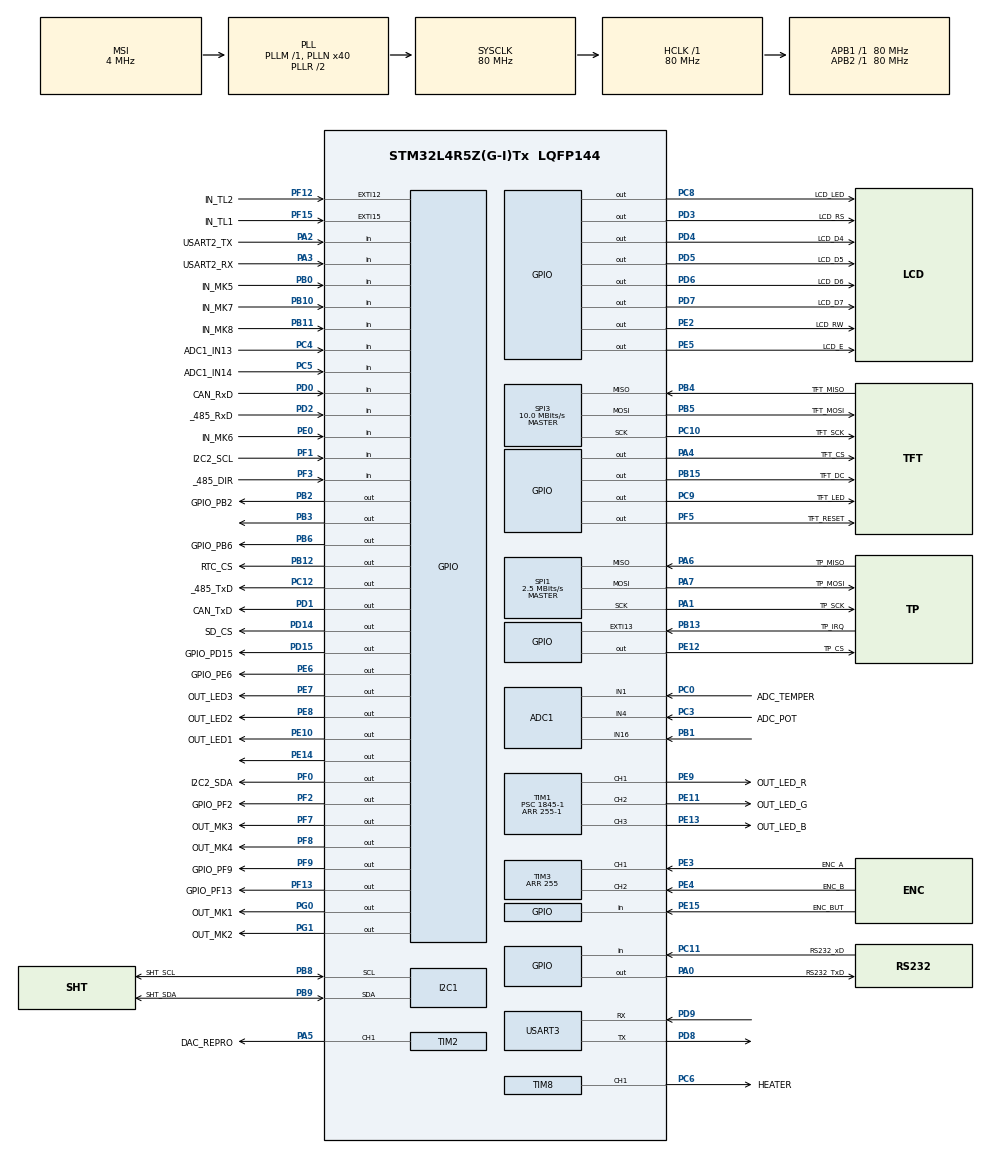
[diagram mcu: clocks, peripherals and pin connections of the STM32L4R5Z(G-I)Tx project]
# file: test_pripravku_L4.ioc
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ADC1.Channel-0\#ChannelRegularConversion=ADC_CHANNEL_4
ADC1.Channel-1\#ChannelRegularConversion=ADC_CHANNEL_1
ADC1.ContinuousConvMode=ENABLE
ADC1.NbrOfConversion=2
ADC1.NbrOfConversionFlag=1
ADC1.OffsetNumber-0\#ChannelRegularConversion=ADC_OFFSET_NONE
ADC1.OffsetNumber-1\#ChannelRegularConversion=ADC_OFFSET_NONE
ADC1.Rank-0\#ChannelRegularConversion=1
ADC1.Rank-1\#ChannelRegularConversion=2
ADC1.SamplingTime-0\#ChannelRegularConversion=ADC_SAMPLETIME_2CYCLES_5
ADC1.SamplingTime-1\#ChannelRegularConversion=ADC_SAMPLETIME_2CYCLES_5
ADC1.master=1
Dma.ADC1.1.Direction=DMA_PERIPH_TO_MEMORY
Dma.ADC1.1.EventEnable=DISABLE
Dma.ADC1.1.Instance=DMA1_Channel2
Dma.ADC1.1.MemDataAlignment=DMA_MDATAALIGN_WORD
Dma.ADC1.1.MemInc=DMA_MINC_ENABLE
Dma.ADC1.1.Mode=DMA_CIRCULAR
Dma.ADC1.1.PeriphDataAlignment=DMA_PDATAALIGN_WORD
Dma.ADC1.1.PeriphInc=DMA_PINC_DISABLE
Dma.ADC1.1.Polarity=HAL_DMAMUX_REQUEST_GEN_RISING
Dma.ADC1.1.Priority=DMA_PRIORITY_LOW
Dma.ADC1.1.RequestNumber=1
Dma.ADC1.1.SignalID=NONE
Dma.ADC1.1.SyncEnable=DISABLE
Dma.ADC1.1.SyncPolarity=HAL_DMAMUX_SYNC_NO_EVENT
Dma.ADC1.1.SyncRequestNumber=1
Dma.ADC1.1.SyncSignalID=NONE
Dma.Request0=SPI3_TX
Dma.Request1=ADC1
Dma.SPI3_TX.0.Direction=DMA_MEMORY_TO_PERIPH
Dma.SPI3_TX.0.EventEnable=DISABLE
Dma.SPI3_TX.0.Instance=DMA1_Channel1
Dma.SPI3_TX.0.MemDataAlignment=DMA_MDATAALIGN_BYTE
Dma.SPI3_TX.0.MemInc=DMA_MINC_ENABLE
Dma.SPI3_TX.0.Mode=DMA_CIRCULAR
Dma.SPI3_TX.0.PeriphDataAlignment=DMA_PDATAALIGN_BYTE
Dma.SPI3_TX.0.PeriphInc=DMA_PINC_DISABLE
Dma.SPI3_TX.0.Polarity=HAL_DMAMUX_REQUEST_GEN_RISING
Dma.SPI3_TX.0.Priority=DMA_PRIORITY_LOW
Dma.SPI3_TX.0.RequestNumber=1
Dma.SPI3_TX.0.SignalID=NONE
Dma.SPI3_TX.0.SyncEnable=DISABLE
Dma.SPI3_TX.0.SyncPolarity=HAL_DMAMUX_SYNC_NO_EVENT
Dma.SPI3_TX.0.SyncRequestNumber=1
Dma.SPI3_TX.0.SyncSignalID=NONE
Mcu.Family=STM32L4
Mcu.Name=STM32L4R5Z(G-I)Tx
Mcu.Package=LQFP144
NVIC.ADC1_IRQn=true\:0\:0\:false\:false\:true\:true\:true
NVIC.DMA1_Channel1_IRQn=true\:0\:0\:false\:false\:true\:false\:true
NVIC.DMA1_Channel2_IRQn=true\:0\:0\:false\:false\:true\:false\:true
NVIC.EXTI15_10_IRQn=true\:1\:0\:true\:false\:true\:true\:true
NVIC.PriorityGroup=NVIC_PRIORITYGROUP_4
NVIC.TIM3_IRQn=true\:0\:0\:false\:false\:true\:true\:true
NVIC.TIM4_IRQn=true\:0\:0\:false\:false\:true\:true\:true
NVIC.TIM5_IRQn=true\:0\:0\:false\:false\:true\:true\:true
NVIC.TIM6_DAC_IRQn=true\:0\:0\:false\:false\:true\:true\:true
PA0.GPIO_Label=RS232_TxD
PA0.Signal=GPIO_Output
PA1.GPIO_Label=TP_SCK
PA1.Mode=Full_Duplex_Master
PA1.Signal=SPI1_SCK
PA2.GPIO_Label=USART2_TX
PA2.Signal=GPIO_Input
PA3.GPIO_Label=USART2_RX
PA3.Signal=GPIO_Input
PA4.GPIO_Label=TFT_CS
PA4.GPIO_Speed=GPIO_SPEED_FREQ_HIGH
PA4.PinState=GPIO_PIN_RESET
PA4.Signal=GPIO_Output
PA5.GPIO_Label=DAC_REPRO
PA5.Signal=S_TIM2_CH1
PA6.GPIO_Label=TP_MISO
PA6.Mode=Full_Duplex_Master
PA6.Signal=SPI1_MISO
PA7.GPIO_Label=TP_MOSI
PA7.Mode=Full_Duplex_Master
PA7.Signal=SPI1_MOSI
PB0.GPIO_Label=IN_MK5
PB0.Signal=GPIO_Input
PB1.Signal=ADCx_IN16
PB10.GPIO_Label=IN_MK7
PB10.Signal=GPIO_Input
PB11.GPIO_Label=IN_MK8
PB11.Signal=GPIO_Input
PB12.GPIO_Label=RTC_CS
PB12.GPIO_Speed=GPIO_SPEED_FREQ_HIGH
PB12.Signal=GPIO_Output
PB13.GPIO_Label=TP_IRQ
PB13.GPIO_ModeDefaultEXTI=GPIO_MODE_IT_RISING_FALLING
PB13.GPIO_PuPd=GPIO_PULLUP
PB13.Signal=GPXTI13
PB15.GPIO_Label=TFT_DC
PB15.GPIO_Speed=GPIO_SPEED_FREQ_HIGH
PB15.Signal=GPIO_Output
PB2.GPIO_Label=GPIO_PB2
PB2.Signal=GPIO_Output
PB3\ (JTDO/TRACESWO).Signal=GPIO_Output
PB4\ (NJTRST).GPIO_Label=TFT_MISO
PB4\ (NJTRST).Mode=Full_Duplex_Master
PB4\ (NJTRST).Signal=SPI3_MISO
PB5.GPIO_Label=TFT_MOSI
PB5.Mode=Full_Duplex_Master
PB5.Signal=SPI3_MOSI
PB6.GPIO_Label=GPIO_PB6
PB6.Signal=GPIO_Output
PB8.GPIO_Label=SHT_SCL
PB8.Mode=I2C
PB8.Signal=I2C1_SCL
PB9.GPIO_Label=SHT_SDA
PB9.Mode=I2C
PB9.Signal=I2C1_SDA
PC0.GPIO_Label=ADC_TEMPER
PC0.Signal=ADCx_IN1
PC10.GPIO_Label=TFT_SCK
PC10.Mode=Full_Duplex_Master
PC10.Signal=SPI3_SCK
PC11.GPIO_Label=RS232_xD
PC11.Signal=GPIO_Input
PC12.GPIO_Label=_485_TxD
PC12.Signal=GPIO_Output
PC3.GPIO_Label=ADC_POT
PC3.Signal=ADCx_IN4
PC4.GPIO_Label=ADC1_IN13
PC4.Signal=GPIO_Input
PC5.GPIO_Label=ADC1_IN14
PC5.Signal=GPIO_Input
PC6.GPIO_Label=HEATER
PC6.Signal=S_TIM8_CH1
PC8.GPIO_Label=LCD_LED
PC8.Signal=GPIO_Output
PC9.GPIO_Label=TFT_LED
PC9.Signal=GPIO_Output
PD0.GPIO_Label=CAN_RxD
PD0.Signal=GPIO_Input
PD1.GPIO_Label=CAN_TxD
PD1.Signal=GPIO_Output
PD14.GPIO_Label=SD_CS
PD14.GPIO_Speed=GPIO_SPEED_FREQ_HIGH
PD14.Signal=GPIO_Output
PD15.GPIO_Label=GPIO_PD15
PD15.Signal=GPIO_Output
PD2.GPIO_Label=_485_RxD
PD2.Signal=GPIO_Input
PD3.GPIO_Label=LCD_RS
PD3.Signal=GPIO_Output
PD4.GPIO_Label=LCD_D4
PD4.Signal=GPIO_Output
PD5.GPIO_Label=LCD_D5
PD5.Signal=GPIO_Output
PD6.GPIO_Label=LCD_D6
PD6.Signal=GPIO_Output
PD7.GPIO_Label=LCD_D7
PD7.Signal=GPIO_Output
PD8.Mode=Asynchronous
PD8.Signal=USART3_TX
PD9.Mode=Asynchronous
PD9.Signal=USART3_RX
PE0.GPIO_Label=IN_MK6
PE0.Signal=GPIO_Input
PE10.GPIO_Label=OUT_LED1
PE10.Signal=GPIO_Output
PE11.GPIO_Label=OUT_LED_G
PE11.Signal=S_TIM1_CH2
PE12.GPIO_Label=TP_CS
PE12.GPIO_Speed=GPIO_SPEED_FREQ_HIGH
PE12.Signal=GPIO_Output
PE13.GPIO_Label=OUT_LED_B
PE13.Signal=S_TIM1_CH3
PE14.Signal=GPIO_Output
PE15.GPIO_Label=ENC_BUT
PE15.Signal=GPIO_Input
PE2.GPIO_Label=LCD_RW
PE2.Signal=GPIO_Output
PE3.GPIO_Label=ENC_A
PE3.Signal=S_TIM3_CH1
PE4.GPIO_Label=ENC_B
PE4.Signal=S_TIM3_CH2
PE5.GPIO_Label=LCD_E
PE5.Signal=GPIO_Output
PE6.GPIO_Label=GPIO_PE6
PE6.Signal=GPIO_Output
PE7.GPIO_Label=OUT_LED3
PE7.Signal=GPIO_Output
PE8.GPIO_Label=OUT_LED2
PE8.Signal=GPIO_Output
PE9.GPIO_Label=OUT_LED_R
PE9.Signal=S_TIM1_CH1
PF0.GPIO_Label=I2C2_SDA
PF0.Signal=GPIO_Output
PF1.GPIO_Label=I2C2_SCL
PF1.Signal=GPIO_Input
PF12.GPIO_Label=IN_TL2
PF12.Signal=GPXTI12
PF13.GPIO_Label=GPIO_PF13
PF13.Signal=GPIO_Output
PF15.GPIO_Label=IN_TL1
PF15.Signal=GPXTI15
PF2.GPIO_Label=GPIO_PF2
PF2.Signal=GPIO_Output
PF3.GPIO_Label=_485_DIR
PF3.Signal=GPIO_Input
PF5.GPIO_Label=TFT_RESET
PF5.GPIO_Speed=GPIO_SPEED_FREQ_HIGH
PF5.Signal=GPIO_Output
PF7.GPIO_Label=OUT_MK3
PF7.GPIO_ModeDefaultOutputPP=GPIO_MODE_OUTPUT_OD
PF7.Signal=GPIO_Output
PF8.GPIO_Label=OUT_MK4
PF8.GPIO_ModeDefaultOutputPP=GPIO_MODE_OUTPUT_OD
PF8.Signal=GPIO_Output
PF9.GPIO_Label=GPIO_PF9
PF9.Signal=GPIO_Output
PG0.GPIO_Label=OUT_MK1
PG0.GPIO_ModeDefaultOutputPP=GPIO_MODE_OUTPUT_OD
PG0.Signal=GPIO_Output
PG1.GPIO_Label=OUT_MK2
PG1.GPIO_ModeDefaultOutputPP=GPIO_MODE_OUTPUT_OD
PG1.Signal=GPIO_Output
PH0-OSC_IN\ (PH0).Mode=HSE-External-Oscillator
PH0-OSC_IN\ (PH0).Signal=RCC_OSC_IN
PH1-OSC_OUT\ (PH1).Mode=HSE-External-Oscillator
PH1-OSC_OUT\ (PH1).Signal=RCC_OSC_OUT
ProjectManager.HeapSize=0x200
ProjectManager.StackSize=0x400
ProjectManager.TargetToolchain=STM32CubeIDE
RCC.48MHZClocksFreq_Value=24000000
RCC.ADCFreq_Value=32000000
RCC.AHBFreq_Value=80000000
RCC.APB1Freq_Value=80000000
RCC.APB1TimFreq_Value=80000000
RCC.APB2Freq_Value=80000000
RCC.APB2TimFreq_Value=80000000
RCC.CortexFreq_Value=80000000
RCC.HCLKFreq_Value=80000000
RCC.HSE_VALUE=8000000
RCC.HSI48_VALUE=48000000
RCC.HSI_VALUE=16000000
RCC.LSE_VALUE=32768
RCC.MSI_VALUE=4000000
RCC.PLLMUL=RCC_PLL_MUL9
RCC.PLLN=40
RCC.PLLSAI1N=16
RCC.PRESCALERUSB=RCC_USBCLKSOURCE_PLL_DIV1_5
RCC.SYSCLKFreq_VALUE=80000000
RCC.SYSCLKSource=RCC_SYSCLKSOURCE_PLLCLK
RCC.SYSCLKSourceVirtual=RCC_SYSCLKSOURCE_PLLCLK
RCC.USBFreq_Value=32000000
RCC.VCOOutputFreq_Value=160000000
SH.ADCx_IN1.0=ADC1_IN1,IN1-Single-Ended
SH.ADCx_IN16.0=ADC1_IN16,IN16-Single-Ended
SH.ADCx_IN4.0=ADC1_IN4,IN4-Single-Ended
SH.S_TIM1_CH1.0=TIM1_CH1,PWM Generation1 CH1
SH.S_TIM1_CH2.0=TIM1_CH2,PWM Generation2 CH2
SH.S_TIM1_CH3.0=TIM1_CH3,PWM Generation3 CH3
SH.S_TIM2_CH1.0=TIM2_CH1,PWM Generation1 CH1
SH.S_TIM3_CH1.0=TIM3_CH1,Encoder_Interface
SH.S_TIM3_CH2.0=TIM3_CH2,Encoder_Interface
SH.S_TIM8_CH1.0=TIM8_CH1,PWM Generation1 CH1
SPI1.BaudRatePrescaler=SPI_BAUDRATEPRESCALER_32
SPI1.CalculateBaudRate=2.5 MBits/s
SPI1.DataSize=SPI_DATASIZE_8BIT
SPI1.Direction=SPI_DIRECTION_2LINES
SPI1.Mode=SPI_MODE_MASTER
SPI1.VirtualType=VM_MASTER
SPI3.BaudRatePrescaler=SPI_BAUDRATEPRESCALER_8
SPI3.CalculateBaudRate=10.0 MBits/s
SPI3.DataSize=SPI_DATASIZE_8BIT
SPI3.Direction=SPI_DIRECTION_2LINES
SPI3.Mode=SPI_MODE_MASTER
SPI3.VirtualType=VM_MASTER
TIM1.Channel-PWM\ Generation1\ CH1=TIM_CHANNEL_1
TIM1.Channel-PWM\ Generation2\ CH2=TIM_CHANNEL_2
TIM1.Channel-PWM\ Generation3\ CH3=TIM_CHANNEL_3
TIM1.Period=255-1
TIM1.Prescaler=1845-1
TIM2.Channel-PWM\ Generation1\ CH1=TIM_CHANNEL_1
TIM2.Period=250-1
TIM2.Prescaler=1280-1
TIM2.TIM_MasterOutputTrigger=TIM_TRGO_UPDATE
TIM3.Period=255
TIM3.TIM_MasterOutputTrigger=TIM_TRGO_RESET
TIM4.Period=500-1
TIM4.Prescaler=8000-1
TIM5.Period=500-1
TIM5.Prescaler=8000-1
TIM6.Period=5000-1
TIM6.Prescaler=8000-1
TIM8.Channel-PWM\ Generation1\ CH1=TIM_CHANNEL_1
TIM8.Period=250-1
TIM8.Prescaler=1280-1
TIM8.TIM_MasterOutputTrigger=TIM_TRGO_UPDATE
TIM8.TIM_MasterOutputTrigger2=TIM_TRGO2_UPDATE
USART3.VirtualMode-Asynchronous=VM_ASYNC
VP_RNG_VS_RNG.Mode=RNG_Activate
VP_TIM1_VS_ClockSourceINT.Mode=Internal
VP_TIM2_VS_ClockSourceINT.Mode=Internal
VP_TIM4_VS_ClockSourceINT.Mode=Internal
VP_TIM5_VS_ClockSourceINT.Mode=Internal
VP_TIM6_VS_ClockSourceINT.Mode=Enable_Timer
VP_TIM8_VS_ClockSourceINT.Mode=Internal
board=NUCLEO-L4R5ZI

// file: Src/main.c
/* USER CODE BEGIN Header */
/**
  ******************************************************************************
  *
  * Author: Pavel Vaner
  *
  ******************************************************************************
  */
/* USER CODE END Header */

#include <my_lib_gui.h>
#include <my_lib_ILI9341.h>
#include <my_lib_keypad4x4.h>
#include <my_lib_LCD16x2.h>
#include <my_lib_MCP795.h>
#include <my_lib_STH20.h>
#include <my_lib_XPT2046.h>
#include "main.h"

/* USER CODE BEGIN Includes */
#include "L4_main_header.h"
#include "stm32l4xx_hal.h"
#include <stdbool.h>
#include "math.h"
/* USER CODE END Includes */

/* USER CODE BEGIN PD */
#define PI 3.1415926
/* USER CODE END PD */

ADC_HandleTypeDef hadc1;
DMA_HandleTypeDef hdma_adc1;

I2C_HandleTypeDef hi2c1;

RNG_HandleTypeDef hrng;

SPI_HandleTypeDef hspi1;
SPI_HandleTypeDef hspi3;
DMA_HandleTypeDef hdma_spi3_tx;

TIM_HandleTypeDef htim1;
TIM_HandleTypeDef htim2;
TIM_HandleTypeDef htim3;
TIM_HandleTypeDef htim4;
TIM_HandleTypeDef htim5;
TIM_HandleTypeDef htim6;
TIM_HandleTypeDef htim8;

UART_HandleTypeDef huart3;

/* USER CODE BEGIN PV */
extern uint16_t TFT9341_WIDTH;
extern uint16_t TFT9341_HEIGHT;
uint8_t dma_spi_fl=0;
uint32_t dma_spi_cnt=1;
uint8_t TFTstav=0;
char str[16];
char str2[16];
char strENC[16];
bool mySwitches[16];
uint8_t RGBcounter;
uint32_t ADCvalues[2];
uint8_t semafor=0;
bool IRQ_flag=false;
Keypad_WiresTypeDef myKeypadStruct;
char strPOT [16];
uint32_t POTvalue=0;
/* USER CODE END PV */

void SystemClock_Config(void);
static void MX_GPIO_Init(void);
static void MX_DMA_Init(void);
static void MX_SPI1_Init(void);
static void MX_SPI3_Init(void);
static void MX_TIM3_Init(void);
static void MX_ADC1_Init(void);
static void MX_USART3_UART_Init(void);
static void MX_I2C1_Init(void);
static void MX_RNG_Init(void);
static void MX_TIM1_Init(void);
static void MX_TIM2_Init(void);
static void MX_TIM8_Init(void);
static void MX_TIM4_Init(void);
static void MX_TIM5_Init(void);
static void MX_TIM6_Init(void);

/* USER CODE BEGIN 0 */
//metoda pro nastaveni RGB ledky
void set_rgb (uint8_t red, uint8_t green, uint8_t blue) //0 je nejvetsi intenzita
{
	htim1.Instance->CCR1 = green;
	htim1.Instance->CCR2 = red;
	htim1.Instance->CCR3 = blue;
}
//metoda volana pri zmene stavu menu
void StavSwitch(void)
{
	  LCD1602_clear();
	  HAL_TIM_PWM_Stop(&htim1, TIM_CHANNEL_1);
	  HAL_TIM_PWM_Stop(&htim1, TIM_CHANNEL_2);
	  HAL_TIM_PWM_Stop(&htim1, TIM_CHANNEL_3);
	  HAL_TIM_Encoder_Stop_IT(&htim3, TIM_CHANNEL_1);
	  HAL_TIM_PWM_Stop(&htim8, TIM_CHANNEL_1);
	  HAL_TIM_PWM_Stop(&htim2, TIM_CHANNEL_1);
	  HAL_TIM_Base_Stop_IT(&htim4);
	  HAL_TIM_Base_Stop_IT(&htim5);
	  HAL_TIM_Base_Stop_IT(&htim6);
	  HAL_GPIO_WritePin(OUT_LED2_GPIO_Port, OUT_LED2_Pin, RESET);
	  HAL_GPIO_WritePin(OUT_LED1_GPIO_Port, OUT_LED1_Pin, RESET);
	  HAL_GPIO_WritePin(OUT_LED3_GPIO_Port, OUT_LED3_Pin, RESET);
}
/* USER CODE END 0 */

int main(void)
{

  /* MCU Configuration--------------------------------------------------------*/

  /* Reset of all peripherals, Initializes the Flash interface and the Systick. */
  HAL_Init();

  /* Configure the system clock */
  SystemClock_Config();

  /* Initialize all configured peripherals */
  MX_GPIO_Init();
  MX_DMA_Init();
  MX_SPI1_Init();
  MX_SPI3_Init();
  MX_TIM3_Init();
  MX_ADC1_Init();
  MX_USART3_UART_Init();
  MX_I2C1_Init();
  MX_RNG_Init();
  MX_TIM1_Init();
  MX_TIM2_Init();
  MX_TIM8_Init();
  MX_TIM4_Init();
  MX_TIM5_Init();
  MX_TIM6_Init();
  /* USER CODE BEGIN 2 */

  //nastaveni promenne myKeypadStruct pro klavesnici 4x4
  myKeypadStruct.OUT0_Port = OUT_MK1_GPIO_Port;
  myKeypadStruct.OUT1_Port = OUT_MK2_GPIO_Port;
  myKeypadStruct.OUT2_Port = OUT_MK3_GPIO_Port;
  myKeypadStruct.OUT3_Port = OUT_MK4_GPIO_Port;
  myKeypadStruct.OUT0pin=OUT_MK1_Pin;
  myKeypadStruct.OUT1pin=OUT_MK2_Pin;
  myKeypadStruct.OUT2pin=OUT_MK3_Pin;
  myKeypadStruct.OUT3pin=OUT_MK4_Pin;
  myKeypadStruct.IN0_Port = IN_MK5_GPIO_Port;
  myKeypadStruct.IN1_Port = IN_MK6_GPIO_Port;
  myKeypadStruct.IN2_Port = IN_MK7_GPIO_Port;
  myKeypadStruct.IN3_Port = IN_MK8_GPIO_Port;
  myKeypadStruct.IN0pin=IN_MK5_Pin;
  myKeypadStruct.IN1pin=IN_MK6_Pin;
  myKeypadStruct.IN2pin=IN_MK7_Pin;
  myKeypadStruct.IN3pin=IN_MK8_Pin;
  //inicializace vsech periferií
  Keypad4x4_Init(&myKeypadStruct);//klavesnice 4x4
  HAL_GPIO_WritePin(LCD_RW_GPIO_Port, LCD_RW_Pin, RESET);
  LCD1602_Begin4BIT(LCD_RS_GPIO_Port,LCD_RS_Pin,LCD_E_GPIO_Port,LCD_E_Pin,LCD_D4_GPIO_Port,LCD_D4_Pin,LCD_D5_Pin,LCD_D6_Pin,LCD_D7_Pin); //LCD dvouradkovy displej
  LCD1602_noCursor();
  LCD1602_noBlink();
  SHT20_Init(&hi2c1);//SHT20 environmentalni cidlo
  TFT9341_Init(TFT_CS_GPIO_Port, TFT_CS_Pin, TFT_DC_GPIO_Port, TFT_DC_Pin, TFT_RESET_GPIO_Port, TFT_RESET_Pin); //TFT displej
  TFT9341_SetRotation(4);
  GUI_page_main();
  XPT2046_Init(&hspi1, TP_CS_GPIO_Port, TP_CS_Pin, TP_IRQ_GPIO_Port, TP_IRQ_Pin); //touch screen
  /* USER CODE END 2 */

  /* Infinite loop */
  /* USER CODE BEGIN WHILE */
  while (1)
  {
	  //pokud bylo vyvoláno přerušení dotykem obrazovky
	  if(IRQ_flag==true)
	  {
		  StavSwitch();
		  IRQ_flag=false;
	  }
	  switch(TFTstav)
	  {
	  	  	case 1://malovani
	  	  		break;
			case 2: //encoder zmena rgb plus hodnota na displej a potak na displej
				HAL_TIM_PWM_Start (&htim1, TIM_CHANNEL_1);
				HAL_TIM_PWM_Start (&htim1, TIM_CHANNEL_2);
				HAL_TIM_PWM_Start (&htim1, TIM_CHANNEL_3);
				HAL_TIM_Encoder_Start_IT(&htim3, TIM_CHANNEL_1);
				RGBcounter=TIM3->CNT;
				LCD1602_1stLine();
				sprintf(strENC,"Encoder:%3d",RGBcounter);
				LCD1602_print(strENC);
				RGBcounter=RGBcounter%6;
				switch(RGBcounter)
				{
						case 0: //red
							set_rgb (0,255,255);
							break;
						case 1: //green
							set_rgb (255,0,255);
							break;
						case 2: //blue
							set_rgb (255,255,0);
							break;
						case 3: //yellow
							set_rgb (0,0,255);
							break;
						case 4: //Cyan
							set_rgb (255,0,0);
							break;
						case 5: //Magenta
							set_rgb (0,255,0);
							break;
				  }
				  HAL_ADC_Start(&hadc1);
			      HAL_ADC_PollForConversion(&hadc1,100);
			      POTvalue = ceil(((float)HAL_ADC_GetValue(&hadc1))/40.3);
			      HAL_ADC_Stop (&hadc1);
			      LCD1602_2ndLine();
			      sprintf(strPOT,"Potak:%3d", POTvalue);
			      LCD1602_print(strPOT);

				break;
			case 3: //teplota a vlhkost
				SHT20_GetValue();
				LCD1602_1stLine();
				sprintf(str,"Teplota:%.*f",2,sht20_info.tempreture);
				LCD1602_print(str);
				LCD1602_2ndLine();
				sprintf(str2,"Vlhkost:%.*f",2, sht20_info.humidity);
				LCD1602_print(str2);
				HAL_Delay(1000);
				break;
			case 4://klavesnice
				LCD1602_1stLine();
				LCD1602_print("Stisknuto:");
				Keypad4x4_ReadKeypad(mySwitches);
				LCD1602_2ndLine();
				uint8_t strIndex=0;
				char data_keys[16];
				for(uint8_t j=0;j<16;j++)
				{
					data_keys[j]=' ';
				}
				uint8_t k=0;
				for(uint8_t i=0;i<16;i++)
				{
					if(!mySwitches[i])
					{
						data_keys[k]=Keypad4x4_GetChar(i);
						k++;
					}
				}
				LCD1602_print(data_keys);
				break;
			case 5://NTC/heater
				HAL_TIM_PWM_Start(&htim8, TIM_CHANNEL_1);   //heater
				HAL_ADC_Start_DMA(&hadc1, ADCvalues, 2);
				LCD1602_1stLine();
				POTvalue=ceil(((float)ADCvalues[0])/40.3);
				sprintf(str,"HEATER:%3d",POTvalue);
				LCD1602_print(str);
				LCD1602_2ndLine();
				sprintf(str2,"NTC:%3d", ADCvalues[1]);
				LCD1602_print(str2);
				HAL_ADC_Stop_DMA(&hadc1);
				htim8.Instance->CCR1=POTvalue;
				break;
			case 6://reproduktor
				HAL_TIM_PWM_Start(&htim2, TIM_CHANNEL_1);   //reproduktor
				HAL_ADC_Start_DMA(&hadc1, ADCvalues, 2);
				LCD1602_1stLine();
				POTvalue=ceil(((float)ADCvalues[0])/40.3);
				sprintf(str,"REPRO:%3d",POTvalue);
				LCD1602_print(str);
				HAL_ADC_Stop_DMA(&hadc1);
				htim2.Instance->CCR1=POTvalue;
				break;
			case 7://semafor
				HAL_TIM_PWM_Start (&htim1, TIM_CHANNEL_1);
				HAL_TIM_PWM_Start (&htim1, TIM_CHANNEL_2);
				HAL_TIM_PWM_Start (&htim1, TIM_CHANNEL_3);
				HAL_TIM_Base_Start_IT(&htim6);
				break;
			case 8://tlacitka
					// osetrani tlacitka metodou polling reaguje na sestupnou hranu
				  if(HAL_GPIO_ReadPin(ENC_BUT_GPIO_Port, ENC_BUT_Pin)==RESET)
				  {
					  while(HAL_GPIO_ReadPin(ENC_BUT_GPIO_Port, ENC_BUT_Pin)!=SET)
					  {
						  HAL_Delay(30);
					  }
					  HAL_GPIO_TogglePin(OUT_LED1_GPIO_Port, OUT_LED1_Pin);
				  }
				  HAL_Delay(10);
				break;
	  }
    /* USER CODE END WHILE */

  }
}

void SystemClock_Config(void)
{
  RCC_OscInitTypeDef RCC_OscInitStruct = {0};
  RCC_ClkInitTypeDef RCC_ClkInitStruct = {0};
  RCC_PeriphCLKInitTypeDef PeriphClkInit = {0};

  /** Configure the main internal regulator output voltage
  */
  if (HAL_PWREx_ControlVoltageScaling(PWR_REGULATOR_VOLTAGE_SCALE1) != HAL_OK)
  {
    Error_Handler();
  }
  /** Initializes the CPU, AHB and APB busses clocks
  */
  RCC_OscInitStruct.OscillatorType = RCC_OSCILLATORTYPE_MSI;
  RCC_OscInitStruct.MSIState = RCC_MSI_ON;
  RCC_OscInitStruct.MSICalibrationValue = 0;
  RCC_OscInitStruct.MSIClockRange = RCC_MSIRANGE_6;
  RCC_OscInitStruct.PLL.PLLState = RCC_PLL_ON;
  RCC_OscInitStruct.PLL.PLLSource = RCC_PLLSOURCE_MSI;
  RCC_OscInitStruct.PLL.PLLM = 1;
  RCC_OscInitStruct.PLL.PLLN = 40;
  RCC_OscInitStruct.PLL.PLLP = RCC_PLLP_DIV2;
  RCC_OscInitStruct.PLL.PLLQ = RCC_PLLQ_DIV2;
  RCC_OscInitStruct.PLL.PLLR = RCC_PLLR_DIV2;
  if (HAL_RCC_OscConfig(&RCC_OscInitStruct) != HAL_OK)
  {
    Error_Handler();
  }
  /** Initializes the CPU, AHB and APB busses clocks
  */
  RCC_ClkInitStruct.ClockType = RCC_CLOCKTYPE_HCLK|RCC_CLOCKTYPE_SYSCLK
                              |RCC_CLOCKTYPE_PCLK1|RCC_CLOCKTYPE_PCLK2;
  RCC_ClkInitStruct.SYSCLKSource = RCC_SYSCLKSOURCE_PLLCLK;
  RCC_ClkInitStruct.AHBCLKDivider = RCC_SYSCLK_DIV1;
  RCC_ClkInitStruct.APB1CLKDivider = RCC_HCLK_DIV1;
  RCC_ClkInitStruct.APB2CLKDivider = RCC_HCLK_DIV1;

  if (HAL_RCC_ClockConfig(&RCC_ClkInitStruct, FLASH_LATENCY_3) != HAL_OK)
  {
    Error_Handler();
  }
  PeriphClkInit.PeriphClockSelection = RCC_PERIPHCLK_USART3|RCC_PERIPHCLK_I2C1
                              |RCC_PERIPHCLK_RNG|RCC_PERIPHCLK_ADC;
  PeriphClkInit.Usart3ClockSelection = RCC_USART3CLKSOURCE_PCLK1;
  PeriphClkInit.I2c1ClockSelection = RCC_I2C1CLKSOURCE_PCLK1;
  PeriphClkInit.AdcClockSelection = RCC_ADCCLKSOURCE_PLLSAI1;
  PeriphClkInit.RngClockSelection = RCC_RNGCLKSOURCE_PLLSAI1;
  PeriphClkInit.PLLSAI1.PLLSAI1Source = RCC_PLLSOURCE_MSI;
  PeriphClkInit.PLLSAI1.PLLSAI1M = 1;
  PeriphClkInit.PLLSAI1.PLLSAI1N = 16;
  PeriphClkInit.PLLSAI1.PLLSAI1P = RCC_PLLP_DIV2;
  PeriphClkInit.PLLSAI1.PLLSAI1Q = RCC_PLLQ_DIV2;
  PeriphClkInit.PLLSAI1.PLLSAI1R = RCC_PLLR_DIV2;
  PeriphClkInit.PLLSAI1.PLLSAI1ClockOut = RCC_PLLSAI1_48M2CLK|RCC_PLLSAI1_ADC1CLK;
  if (HAL_RCCEx_PeriphCLKConfig(&PeriphClkInit) != HAL_OK)
  {
    Error_Handler();
  }
}

static void MX_ADC1_Init(void)
{

  ADC_ChannelConfTypeDef sConfig = {0};

  /** Common config
  */
  hadc1.Instance = ADC1;
  hadc1.Init.ClockPrescaler = ADC_CLOCK_ASYNC_DIV1;
  hadc1.Init.Resolution = ADC_RESOLUTION_12B;
  hadc1.Init.DataAlign = ADC_DATAALIGN_RIGHT;
  hadc1.Init.ScanConvMode = ADC_SCAN_ENABLE;
  hadc1.Init.EOCSelection = ADC_EOC_SINGLE_CONV;
  hadc1.Init.LowPowerAutoWait = DISABLE;
  hadc1.Init.ContinuousConvMode = ENABLE;
  hadc1.Init.NbrOfConversion = 2;
  hadc1.Init.DiscontinuousConvMode = DISABLE;
  hadc1.Init.NbrOfDiscConversion = 1;
  hadc1.Init.ExternalTrigConv = ADC_SOFTWARE_START;
  hadc1.Init.ExternalTrigConvEdge = ADC_EXTERNALTRIGCONVEDGE_NONE;
  hadc1.Init.DMAContinuousRequests = DISABLE;
  hadc1.Init.Overrun = ADC_OVR_DATA_PRESERVED;
  hadc1.Init.OversamplingMode = DISABLE;
  if (HAL_ADC_Init(&hadc1) != HAL_OK)
  {
    Error_Handler();
  }
  /** Configure Regular Channel
  */
  sConfig.Channel = ADC_CHANNEL_4;
  sConfig.Rank = ADC_REGULAR_RANK_1;
  sConfig.SamplingTime = ADC_SAMPLETIME_2CYCLES_5;
  sConfig.SingleDiff = ADC_SINGLE_ENDED;
  sConfig.OffsetNumber = ADC_OFFSET_NONE;
  sConfig.Offset = 0;
  if (HAL_ADC_ConfigChannel(&hadc1, &sConfig) != HAL_OK)
  {
    Error_Handler();
  }
  /** Configure Regular Channel
  */
  sConfig.Channel = ADC_CHANNEL_1;
  sConfig.Rank = ADC_REGULAR_RANK_2;
  if (HAL_ADC_ConfigChannel(&hadc1, &sConfig) != HAL_OK)
  {
    Error_Handler();
  }

}

static void MX_I2C1_Init(void)
{

  hi2c1.Instance = I2C1;
  hi2c1.Init.Timing = 0x10909CEC;
  hi2c1.Init.OwnAddress1 = 0;
  hi2c1.Init.AddressingMode = I2C_ADDRESSINGMODE_7BIT;
  hi2c1.Init.DualAddressMode = I2C_DUALADDRESS_DISABLE;
  hi2c1.Init.OwnAddress2 = 0;
  hi2c1.Init.OwnAddress2Masks = I2C_OA2_NOMASK;
  hi2c1.Init.GeneralCallMode = I2C_GENERALCALL_DISABLE;
  hi2c1.Init.NoStretchMode = I2C_NOSTRETCH_DISABLE;
  if (HAL_I2C_Init(&hi2c1) != HAL_OK)
  {
    Error_Handler();
  }
  /** Configure Analogue filter
  */
  if (HAL_I2CEx_ConfigAnalogFilter(&hi2c1, I2C_ANALOGFILTER_ENABLE) != HAL_OK)
  {
    Error_Handler();
  }
  /** Configure Digital filter
  */
  if (HAL_I2CEx_ConfigDigitalFilter(&hi2c1, 0) != HAL_OK)
  {
    Error_Handler();
  }

}

static void MX_RNG_Init(void)
{

  hrng.Instance = RNG;
  hrng.Init.ClockErrorDetection = RNG_CED_ENABLE;
  if (HAL_RNG_Init(&hrng) != HAL_OK)
  {
    Error_Handler();
  }

}

static void MX_SPI1_Init(void)
{

  /* SPI1 parameter configuration*/
  hspi1.Instance = SPI1;
  hspi1.Init.Mode = SPI_MODE_MASTER;
  hspi1.Init.Direction = SPI_DIRECTION_2LINES;
  hspi1.Init.DataSize = SPI_DATASIZE_8BIT;
  hspi1.Init.CLKPolarity = SPI_POLARITY_LOW;
  hspi1.Init.CLKPhase = SPI_PHASE_1EDGE;
  hspi1.Init.NSS = SPI_NSS_SOFT;
  hspi1.Init.BaudRatePrescaler = SPI_BAUDRATEPRESCALER_32;
  hspi1.Init.FirstBit = SPI_FIRSTBIT_MSB;
  hspi1.Init.TIMode = SPI_TIMODE_DISABLE;
  hspi1.Init.CRCCalculation = SPI_CRCCALCULATION_DISABLE;
  hspi1.Init.CRCPolynomial = 7;
  hspi1.Init.CRCLength = SPI_CRC_LENGTH_DATASIZE;
  hspi1.Init.NSSPMode = SPI_NSS_PULSE_ENABLE;
  if (HAL_SPI_Init(&hspi1) != HAL_OK)
  {
    Error_Handler();
  }

}

static void MX_SPI3_Init(void)
{

  /* SPI3 parameter configuration*/
  hspi3.Instance = SPI3;
  hspi3.Init.Mode = SPI_MODE_MASTER;
  hspi3.Init.Direction = SPI_DIRECTION_2LINES;
  hspi3.Init.DataSize = SPI_DATASIZE_8BIT;
  hspi3.Init.CLKPolarity = SPI_POLARITY_LOW;
  hspi3.Init.CLKPhase = SPI_PHASE_1EDGE;
  hspi3.Init.NSS = SPI_NSS_SOFT;
  hspi3.Init.BaudRatePrescaler = SPI_BAUDRATEPRESCALER_8;
  hspi3.Init.FirstBit = SPI_FIRSTBIT_MSB;
  hspi3.Init.TIMode = SPI_TIMODE_DISABLE;
  hspi3.Init.CRCCalculation = SPI_CRCCALCULATION_DISABLE;
  hspi3.Init.CRCPolynomial = 7;
  hspi3.Init.CRCLength = SPI_CRC_LENGTH_DATASIZE;
  hspi3.Init.NSSPMode = SPI_NSS_PULSE_ENABLE;
  if (HAL_SPI_Init(&hspi3) != HAL_OK)
  {
    Error_Handler();
  }

}

static void MX_TIM1_Init(void)
{

  TIM_ClockConfigTypeDef sClockSourceConfig = {0};
  TIM_MasterConfigTypeDef sMasterConfig = {0};
  TIM_OC_InitTypeDef sConfigOC = {0};
  TIM_BreakDeadTimeConfigTypeDef sBreakDeadTimeConfig = {0};

  htim1.Instance = TIM1;
  htim1.Init.Prescaler = 1845-1;
  htim1.Init.CounterMode = TIM_COUNTERMODE_UP;
  htim1.Init.Period = 255-1;
  htim1.Init.ClockDivision = TIM_CLOCKDIVISION_DIV1;
  htim1.Init.RepetitionCounter = 0;
  htim1.Init.AutoReloadPreload = TIM_AUTORELOAD_PRELOAD_DISABLE;
  if (HAL_TIM_Base_Init(&htim1) != HAL_OK)
  {
    Error_Handler();
  }
  sClockSourceConfig.ClockSource = TIM_CLOCKSOURCE_INTERNAL;
  if (HAL_TIM_ConfigClockSource(&htim1, &sClockSourceConfig) != HAL_OK)
  {
    Error_Handler();
  }
  if (HAL_TIM_PWM_Init(&htim1) != HAL_OK)
  {
    Error_Handler();
  }
  sMasterConfig.MasterOutputTrigger = TIM_TRGO_RESET;
  sMasterConfig.MasterOutputTrigger2 = TIM_TRGO2_RESET;
  sMasterConfig.MasterSlaveMode = TIM_MASTERSLAVEMODE_DISABLE;
  if (HAL_TIMEx_MasterConfigSynchronization(&htim1, &sMasterConfig) != HAL_OK)
  {
    Error_Handler();
  }
  sConfigOC.OCMode = TIM_OCMODE_PWM1;
  sConfigOC.Pulse = 0;
  sConfigOC.OCPolarity = TIM_OCPOLARITY_HIGH;
  sConfigOC.OCNPolarity = TIM_OCNPOLARITY_HIGH;
  sConfigOC.OCFastMode = TIM_OCFAST_DISABLE;
  sConfigOC.OCIdleState = TIM_OCIDLESTATE_RESET;
  sConfigOC.OCNIdleState = TIM_OCNIDLESTATE_RESET;
  if (HAL_TIM_PWM_ConfigChannel(&htim1, &sConfigOC, TIM_CHANNEL_1) != HAL_OK)
  {
    Error_Handler();
  }
  if (HAL_TIM_PWM_ConfigChannel(&htim1, &sConfigOC, TIM_CHANNEL_2) != HAL_OK)
  {
    Error_Handler();
  }
  if (HAL_TIM_PWM_ConfigChannel(&htim1, &sConfigOC, TIM_CHANNEL_3) != HAL_OK)
  {
    Error_Handler();
  }
  sBreakDeadTimeConfig.OffStateRunMode = TIM_OSSR_DISABLE;
  sBreakDeadTimeConfig.OffStateIDLEMode = TIM_OSSI_DISABLE;
  sBreakDeadTimeConfig.LockLevel = TIM_LOCKLEVEL_OFF;
  sBreakDeadTimeConfig.DeadTime = 0;
  sBreakDeadTimeConfig.BreakState = TIM_BREAK_DISABLE;
  sBreakDeadTimeConfig.BreakPolarity = TIM_BREAKPOLARITY_HIGH;
  sBreakDeadTimeConfig.BreakFilter = 0;
  sBreakDeadTimeConfig.Break2State = TIM_BREAK2_DISABLE;
  sBreakDeadTimeConfig.Break2Polarity = TIM_BREAK2POLARITY_HIGH;
  sBreakDeadTimeConfig.Break2Filter = 0;
  sBreakDeadTimeConfig.AutomaticOutput = TIM_AUTOMATICOUTPUT_DISABLE;
  if (HAL_TIMEx_ConfigBreakDeadTime(&htim1, &sBreakDeadTimeConfig) != HAL_OK)
  {
    Error_Handler();
  }
  HAL_TIM_MspPostInit(&htim1);

}

static void MX_TIM2_Init(void)
{

  TIM_ClockConfigTypeDef sClockSourceConfig = {0};
  TIM_MasterConfigTypeDef sMasterConfig = {0};
  TIM_OC_InitTypeDef sConfigOC = {0};

  htim2.Instance = TIM2;
  htim2.Init.Prescaler = 1280-1;
  htim2.Init.CounterMode = TIM_COUNTERMODE_UP;
  htim2.Init.Period = 250-1;
  htim2.Init.ClockDivision = TIM_CLOCKDIVISION_DIV1;
  htim2.Init.AutoReloadPreload = TIM_AUTORELOAD_PRELOAD_DISABLE;
  if (HAL_TIM_Base_Init(&htim2) != HAL_OK)
  {
    Error_Handler();
  }
  sClockSourceConfig.ClockSource = TIM_CLOCKSOURCE_INTERNAL;
  if (HAL_TIM_ConfigClockSource(&htim2, &sClockSourceConfig) != HAL_OK)
  {
    Error_Handler();
  }
  if (HAL_TIM_PWM_Init(&htim2) != HAL_OK)
  {
    Error_Handler();
  }
  sMasterConfig.MasterOutputTrigger = TIM_TRGO_UPDATE;
  sMasterConfig.MasterSlaveMode = TIM_MASTERSLAVEMODE_DISABLE;
  if (HAL_TIMEx_MasterConfigSynchronization(&htim2, &sMasterConfig) != HAL_OK)
  {
    Error_Handler();
  }
  sConfigOC.OCMode = TIM_OCMODE_PWM1;
  sConfigOC.Pulse = 0;
  sConfigOC.OCPolarity = TIM_OCPOLARITY_HIGH;
  sConfigOC.OCFastMode = TIM_OCFAST_DISABLE;
  if (HAL_TIM_PWM_ConfigChannel(&htim2, &sConfigOC, TIM_CHANNEL_1) != HAL_OK)
  {
    Error_Handler();
  }
  HAL_TIM_MspPostInit(&htim2);

}

static void MX_TIM3_Init(void)
{

  TIM_Encoder_InitTypeDef sConfig = {0};
  TIM_MasterConfigTypeDef sMasterConfig = {0};

  htim3.Instance = TIM3;
  htim3.Init.Prescaler = 0;
  htim3.Init.CounterMode = TIM_COUNTERMODE_UP;
  htim3.Init.Period = 255;
  htim3.Init.ClockDivision = TIM_CLOCKDIVISION_DIV1;
  htim3.Init.AutoReloadPreload = TIM_AUTORELOAD_PRELOAD_DISABLE;
  sConfig.EncoderMode = TIM_ENCODERMODE_TI1;
  sConfig.IC1Polarity = TIM_ICPOLARITY_RISING;
  sConfig.IC1Selection = TIM_ICSELECTION_DIRECTTI;
  sConfig.IC1Prescaler = TIM_ICPSC_DIV1;
  sConfig.IC1Filter = 0;
  sConfig.IC2Polarity = TIM_ICPOLARITY_RISING;
  sConfig.IC2Selection = TIM_ICSELECTION_DIRECTTI;
  sConfig.IC2Prescaler = TIM_ICPSC_DIV1;
  sConfig.IC2Filter = 0;
  if (HAL_TIM_Encoder_Init(&htim3, &sConfig) != HAL_OK)
  {
    Error_Handler();
  }
  sMasterConfig.MasterOutputTrigger = TIM_TRGO_RESET;
  sMasterConfig.MasterSlaveMode = TIM_MASTERSLAVEMODE_DISABLE;
  if (HAL_TIMEx_MasterConfigSynchronization(&htim3, &sMasterConfig) != HAL_OK)
  {
    Error_Handler();
  }

}

static void MX_TIM4_Init(void)
{

  TIM_ClockConfigTypeDef sClockSourceConfig = {0};
  TIM_MasterConfigTypeDef sMasterConfig = {0};

  htim4.Instance = TIM4;
  htim4.Init.Prescaler = 8000-1;
  htim4.Init.CounterMode = TIM_COUNTERMODE_UP;
  htim4.Init.Period = 500-1;
  htim4.Init.ClockDivision = TIM_CLOCKDIVISION_DIV1;
  htim4.Init.AutoReloadPreload = TIM_AUTORELOAD_PRELOAD_DISABLE;
  if (HAL_TIM_Base_Init(&htim4) != HAL_OK)
  {
    Error_Handler();
  }
  sClockSourceConfig.ClockSource = TIM_CLOCKSOURCE_INTERNAL;
  if (HAL_TIM_ConfigClockSource(&htim4, &sClockSourceConfig) != HAL_OK)
  {
    Error_Handler();
  }
  sMasterConfig.MasterOutputTrigger = TIM_TRGO_RESET;
  sMasterConfig.MasterSlaveMode = TIM_MASTERSLAVEMODE_DISABLE;
  if (HAL_TIMEx_MasterConfigSynchronization(&htim4, &sMasterConfig) != HAL_OK)
  {
    Error_Handler();
  }

}

static void MX_TIM5_Init(void)
{

  TIM_ClockConfigTypeDef sClockSourceConfig = {0};
  TIM_MasterConfigTypeDef sMasterConfig = {0};

  htim5.Instance = TIM5;
  htim5.Init.Prescaler = 8000-1;
  htim5.Init.CounterMode = TIM_COUNTERMODE_UP;
  htim5.Init.Period = 500-1;
  htim5.Init.ClockDivision = TIM_CLOCKDIVISION_DIV1;
  htim5.Init.AutoReloadPreload = TIM_AUTORELOAD_PRELOAD_DISABLE;
  if (HAL_TIM_Base_Init(&htim5) != HAL_OK)
  {
    Error_Handler();
  }
  sClockSourceConfig.ClockSource = TIM_CLOCKSOURCE_INTERNAL;
  if (HAL_TIM_ConfigClockSource(&htim5, &sClockSourceConfig) != HAL_OK)
  {
    Error_Handler();
  }
  sMasterConfig.MasterOutputTrigger = TIM_TRGO_RESET;
  sMasterConfig.MasterSlaveMode = TIM_MASTERSLAVEMODE_DISABLE;
  if (HAL_TIMEx_MasterConfigSynchronization(&htim5, &sMasterConfig) != HAL_OK)
  {
    Error_Handler();
  }

}

static void MX_TIM6_Init(void)
{

  TIM_MasterConfigTypeDef sMasterConfig = {0};

  htim6.Instance = TIM6;
  htim6.Init.Prescaler = 8000-1;
  htim6.Init.CounterMode = TIM_COUNTERMODE_UP;
  htim6.Init.Period = 5000-1;
  htim6.Init.AutoReloadPreload = TIM_AUTORELOAD_PRELOAD_DISABLE;
  if (HAL_TIM_Base_Init(&htim6) != HAL_OK)
  {
    Error_Handler();
  }
  sMasterConfig.MasterOutputTrigger = TIM_TRGO_RESET;
  sMasterConfig.MasterSlaveMode = TIM_MASTERSLAVEMODE_DISABLE;
  if (HAL_TIMEx_MasterConfigSynchronization(&htim6, &sMasterConfig) != HAL_OK)
  {
    Error_Handler();
  }

}

static void MX_TIM8_Init(void)
{

  TIM_ClockConfigTypeDef sClockSourceConfig = {0};
  TIM_MasterConfigTypeDef sMasterConfig = {0};
  TIM_OC_InitTypeDef sConfigOC = {0};
  TIM_BreakDeadTimeConfigTypeDef sBreakDeadTimeConfig = {0};

  htim8.Instance = TIM8;
  htim8.Init.Prescaler = 1280-1;
  htim8.Init.CounterMode = TIM_COUNTERMODE_UP;
  htim8.Init.Period = 250-1;
  htim8.Init.ClockDivision = TIM_CLOCKDIVISION_DIV1;
  htim8.Init.RepetitionCounter = 0;
  htim8.Init.AutoReloadPreload = TIM_AUTORELOAD_PRELOAD_DISABLE;
  if (HAL_TIM_Base_Init(&htim8) != HAL_OK)
  {
    Error_Handler();
  }
  sClockSourceConfig.ClockSource = TIM_CLOCKSOURCE_INTERNAL;
  if (HAL_TIM_ConfigClockSource(&htim8, &sClockSourceConfig) != HAL_OK)
  {
    Error_Handler();
  }
  if (HAL_TIM_PWM_Init(&htim8) != HAL_OK)
  {
    Error_Handler();
  }
  sMasterConfig.MasterOutputTrigger = TIM_TRGO_UPDATE;
  sMasterConfig.MasterOutputTrigger2 = TIM_TRGO2_UPDATE;
  sMasterConfig.MasterSlaveMode = TIM_MASTERSLAVEMODE_DISABLE;
  if (HAL_TIMEx_MasterConfigSynchronization(&htim8, &sMasterConfig) != HAL_OK)
  {
    Error_Handler();
  }
  sConfigOC.OCMode = TIM_OCMODE_PWM1;
  sConfigOC.Pulse = 0;
  sConfigOC.OCPolarity = TIM_OCPOLARITY_HIGH;
  sConfigOC.OCNPolarity = TIM_OCNPOLARITY_HIGH;
  sConfigOC.OCFastMode = TIM_OCFAST_DISABLE;
  sConfigOC.OCIdleState = TIM_OCIDLESTATE_RESET;
  sConfigOC.OCNIdleState = TIM_OCNIDLESTATE_RESET;
  if (HAL_TIM_PWM_ConfigChannel(&htim8, &sConfigOC, TIM_CHANNEL_1) != HAL_OK)
  {
    Error_Handler();
  }
  sBreakDeadTimeConfig.OffStateRunMode = TIM_OSSR_DISABLE;
  sBreakDeadTimeConfig.OffStateIDLEMode = TIM_OSSI_DISABLE;
  sBreakDeadTimeConfig.LockLevel = TIM_LOCKLEVEL_OFF;
  sBreakDeadTimeConfig.DeadTime = 0;
  sBreakDeadTimeConfig.BreakState = TIM_BREAK_DISABLE;
  sBreakDeadTimeConfig.BreakPolarity = TIM_BREAKPOLARITY_HIGH;
  sBreakDeadTimeConfig.BreakFilter = 0;
  sBreakDeadTimeConfig.Break2State = TIM_BREAK2_DISABLE;
  sBreakDeadTimeConfig.Break2Polarity = TIM_BREAK2POLARITY_HIGH;
  sBreakDeadTimeConfig.Break2Filter = 0;
  sBreakDeadTimeConfig.AutomaticOutput = TIM_AUTOMATICOUTPUT_DISABLE;
  if (HAL_TIMEx_ConfigBreakDeadTime(&htim8, &sBreakDeadTimeConfig) != HAL_OK)
  {
    Error_Handler();
  }
  HAL_TIM_MspPostInit(&htim8);

}

static void MX_USART3_UART_Init(void)
{

  huart3.Instance = USART3;
  huart3.Init.BaudRate = 115200;
  huart3.Init.WordLength = UART_WORDLENGTH_8B;
  huart3.Init.StopBits = UART_STOPBITS_1;
  huart3.Init.Parity = UART_PARITY_NONE;
  huart3.Init.Mode = UART_MODE_TX_RX;
  huart3.Init.HwFlowCtl = UART_HWCONTROL_NONE;
  huart3.Init.OverSampling = UART_OVERSAMPLING_16;
  huart3.Init.OneBitSampling = UART_ONE_BIT_SAMPLE_DISABLE;
  huart3.Init.ClockPrescaler = UART_PRESCALER_DIV1;
  huart3.AdvancedInit.AdvFeatureInit = UART_ADVFEATURE_NO_INIT;
  if (HAL_UART_Init(&huart3) != HAL_OK)
  {
    Error_Handler();
  }
  if (HAL_UARTEx_SetTxFifoThreshold(&huart3, UART_TXFIFO_THRESHOLD_1_8) != HAL_OK)
  {
    Error_Handler();
  }
  if (HAL_UARTEx_SetRxFifoThreshold(&huart3, UART_RXFIFO_THRESHOLD_1_8) != HAL_OK)
  {
    Error_Handler();
  }
  if (HAL_UARTEx_DisableFifoMode(&huart3) != HAL_OK)
  {
    Error_Handler();
  }

}

static void MX_DMA_Init(void)
{

  /* DMA controller clock enable */
  __HAL_RCC_DMAMUX1_CLK_ENABLE();
  __HAL_RCC_DMA1_CLK_ENABLE();

  /* DMA interrupt init */
  /* DMA1_Channel1_IRQn interrupt configuration */
  HAL_NVIC_SetPriority(DMA1_Channel1_IRQn, 0, 0);
  HAL_NVIC_EnableIRQ(DMA1_Channel1_IRQn);
  /* DMA1_Channel2_IRQn interrupt configuration */
  HAL_NVIC_SetPriority(DMA1_Channel2_IRQn, 0, 0);
  HAL_NVIC_EnableIRQ(DMA1_Channel2_IRQn);

}

static void MX_GPIO_Init(void)
{
  GPIO_InitTypeDef GPIO_InitStruct = {0};

  /* GPIO Ports Clock Enable */
  __HAL_RCC_GPIOE_CLK_ENABLE();
  __HAL_RCC_GPIOF_CLK_ENABLE();
  __HAL_RCC_GPIOH_CLK_ENABLE();
  __HAL_RCC_GPIOC_CLK_ENABLE();
  __HAL_RCC_GPIOA_CLK_ENABLE();
  __HAL_RCC_GPIOB_CLK_ENABLE();
  __HAL_RCC_GPIOG_CLK_ENABLE();
  __HAL_RCC_GPIOD_CLK_ENABLE();

  /*Configure GPIO pin Output Level */
  HAL_GPIO_WritePin(GPIOE, LCD_RW_Pin|LCD_E_Pin|GPIO_PE6_Pin|OUT_LED3_Pin
                          |OUT_LED2_Pin|OUT_LED1_Pin|TP_CS_Pin|GPIO_PIN_14, GPIO_PIN_RESET);

  /*Configure GPIO pin Output Level */
  HAL_GPIO_WritePin(GPIOF, I2C2_SDA_Pin|GPIO_PF2_Pin|TFT_RESET_Pin|OUT_MK3_Pin
                          |OUT_MK4_Pin|GPIO_PF9_Pin|GPIO_PF13_Pin, GPIO_PIN_RESET);

  /*Configure GPIO pin Output Level */
  HAL_GPIO_WritePin(GPIOA, RS232_TxD_Pin|TFT_CS_Pin, GPIO_PIN_RESET);

  /*Configure GPIO pin Output Level */
  HAL_GPIO_WritePin(GPIOB, GPIO_PB2_Pin|RTC_CS_Pin|TFT_DC_Pin|GPIO_PIN_3
                          |GPIO_PB6_Pin, GPIO_PIN_RESET);

  /*Configure GPIO pin Output Level */
  HAL_GPIO_WritePin(GPIOG, OUT_MK1_Pin|OUT_MK2_Pin, GPIO_PIN_RESET);

  /*Configure GPIO pin Output Level */
  HAL_GPIO_WritePin(GPIOD, SD_CS_Pin|GPIO_PD15_Pin|CAN_TxD_Pin|LCD_RS_Pin
                          |LCD_D4_Pin|LCD_D5_Pin|LCD_D6_Pin|LCD_D7_Pin, GPIO_PIN_RESET);

  /*Configure GPIO pin Output Level */
  HAL_GPIO_WritePin(GPIOC, LCD_LED_Pin|TFT_LED_Pin|_485_TxD_Pin, GPIO_PIN_RESET);

  /*Configure GPIO pins : LCD_RW_Pin LCD_E_Pin GPIO_PE6_Pin OUT_LED3_Pin
                           OUT_LED2_Pin OUT_LED1_Pin PE14 */
  GPIO_InitStruct.Pin = LCD_RW_Pin|LCD_E_Pin|GPIO_PE6_Pin|OUT_LED3_Pin
                          |OUT_LED2_Pin|OUT_LED1_Pin|GPIO_PIN_14;
  GPIO_InitStruct.Mode = GPIO_MODE_OUTPUT_PP;
  GPIO_InitStruct.Pull = GPIO_NOPULL;
  GPIO_InitStruct.Speed = GPIO_SPEED_FREQ_LOW;
  HAL_GPIO_Init(GPIOE, &GPIO_InitStruct);

  /*Configure GPIO pins : I2C2_SDA_Pin GPIO_PF2_Pin GPIO_PF9_Pin GPIO_PF13_Pin */
  GPIO_InitStruct.Pin = I2C2_SDA_Pin|GPIO_PF2_Pin|GPIO_PF9_Pin|GPIO_PF13_Pin;
  GPIO_InitStruct.Mode = GPIO_MODE_OUTPUT_PP;
  GPIO_InitStruct.Pull = GPIO_NOPULL;
  GPIO_InitStruct.Speed = GPIO_SPEED_FREQ_LOW;
  HAL_GPIO_Init(GPIOF, &GPIO_InitStruct);

  /*Configure GPIO pins : I2C2_SCL_Pin _485_DIR_Pin */
  GPIO_InitStruct.Pin = I2C2_SCL_Pin|_485_DIR_Pin;
  GPIO_InitStruct.Mode = GPIO_MODE_INPUT;
  GPIO_InitStruct.Pull = GPIO_NOPULL;
  HAL_GPIO_Init(GPIOF, &GPIO_InitStruct);

  /*Configure GPIO pin : TFT_RESET_Pin */
  GPIO_InitStruct.Pin = TFT_RESET_Pin;
  GPIO_InitStruct.Mode = GPIO_MODE_OUTPUT_PP;
  GPIO_InitStruct.Pull = GPIO_NOPULL;
  GPIO_InitStruct.Speed = GPIO_SPEED_FREQ_HIGH;
  HAL_GPIO_Init(TFT_RESET_GPIO_Port, &GPIO_InitStruct);

  /*Configure GPIO pins : OUT_MK3_Pin OUT_MK4_Pin */
  GPIO_InitStruct.Pin = OUT_MK3_Pin|OUT_MK4_Pin;
  GPIO_InitStruct.Mode = GPIO_MODE_OUTPUT_OD;
  GPIO_InitStruct.Pull = GPIO_NOPULL;
  GPIO_InitStruct.Speed = GPIO_SPEED_FREQ_LOW;
  HAL_GPIO_Init(GPIOF, &GPIO_InitStruct);

  /*Configure GPIO pin : RS232_TxD_Pin */
  GPIO_InitStruct.Pin = RS232_TxD_Pin;
  GPIO_InitStruct.Mode = GPIO_MODE_OUTPUT_PP;
  GPIO_InitStruct.Pull = GPIO_NOPULL;
  GPIO_InitStruct.Speed = GPIO_SPEED_FREQ_LOW;
  HAL_GPIO_Init(RS232_TxD_GPIO_Port, &GPIO_InitStruct);

  /*Configure GPIO pins : USART2_TX_Pin USART2_RX_Pin */
  GPIO_InitStruct.Pin = USART2_TX_Pin|USART2_RX_Pin;
  GPIO_InitStruct.Mode = GPIO_MODE_INPUT;
  GPIO_InitStruct.Pull = GPIO_NOPULL;
  HAL_GPIO_Init(GPIOA, &GPIO_InitStruct);

  /*Configure GPIO pin : TFT_CS_Pin */
  GPIO_InitStruct.Pin = TFT_CS_Pin;
  GPIO_InitStruct.Mode = GPIO_MODE_OUTPUT_PP;
  GPIO_InitStruct.Pull = GPIO_NOPULL;
  GPIO_InitStruct.Speed = GPIO_SPEED_FREQ_HIGH;
  HAL_GPIO_Init(TFT_CS_GPIO_Port, &GPIO_InitStruct);

  /*Configure GPIO pins : ADC1_IN13_Pin ADC1_IN14_Pin RS232_xD_Pin */
  GPIO_InitStruct.Pin = ADC1_IN13_Pin|ADC1_IN14_Pin|RS232_xD_Pin;
  GPIO_InitStruct.Mode = GPIO_MODE_INPUT;
  GPIO_InitStruct.Pull = GPIO_NOPULL;
  HAL_GPIO_Init(GPIOC, &GPIO_InitStruct);

  /*Configure GPIO pins : IN_MK5_Pin IN_MK7_Pin IN_MK8_Pin */
  GPIO_InitStruct.Pin = IN_MK5_Pin|IN_MK7_Pin|IN_MK8_Pin;
  GPIO_InitStruct.Mode = GPIO_MODE_INPUT;
  GPIO_InitStruct.Pull = GPIO_NOPULL;
  HAL_GPIO_Init(GPIOB, &GPIO_InitStruct);

  /*Configure GPIO pins : GPIO_PB2_Pin PB3 GPIO_PB6_Pin */
  GPIO_InitStruct.Pin = GPIO_PB2_Pin|GPIO_PIN_3|GPIO_PB6_Pin;
  GPIO_InitStruct.Mode = GPIO_MODE_OUTPUT_PP;
  GPIO_InitStruct.Pull = GPIO_NOPULL;
  GPIO_InitStruct.Speed = GPIO_SPEED_FREQ_LOW;
  HAL_GPIO_Init(GPIOB, &GPIO_InitStruct);

  /*Configure GPIO pins : IN_TL2_Pin IN_TL1_Pin */
  GPIO_InitStruct.Pin = IN_TL2_Pin|IN_TL1_Pin;
  GPIO_InitStruct.Mode = GPIO_MODE_IT_RISING;
  GPIO_InitStruct.Pull = GPIO_NOPULL;
  HAL_GPIO_Init(GPIOF, &GPIO_InitStruct);

  /*Configure GPIO pins : OUT_MK1_Pin OUT_MK2_Pin */
  GPIO_InitStruct.Pin = OUT_MK1_Pin|OUT_MK2_Pin;
  GPIO_InitStruct.Mode = GPIO_MODE_OUTPUT_OD;
  GPIO_InitStruct.Pull = GPIO_NOPULL;
  GPIO_InitStruct.Speed = GPIO_SPEED_FREQ_LOW;
  HAL_GPIO_Init(GPIOG, &GPIO_InitStruct);

  /*Configure GPIO pin : TP_CS_Pin */
  GPIO_InitStruct.Pin = TP_CS_Pin;
  GPIO_InitStruct.Mode = GPIO_MODE_OUTPUT_PP;
  GPIO_InitStruct.Pull = GPIO_NOPULL;
  GPIO_InitStruct.Speed = GPIO_SPEED_FREQ_HIGH;
  HAL_GPIO_Init(TP_CS_GPIO_Port, &GPIO_InitStruct);

  /*Configure GPIO pins : ENC_BUT_Pin IN_MK6_Pin */
  GPIO_InitStruct.Pin = ENC_BUT_Pin|IN_MK6_Pin;
  GPIO_InitStruct.Mode = GPIO_MODE_INPUT;
  GPIO_InitStruct.Pull = GPIO_NOPULL;
  HAL_GPIO_Init(GPIOE, &GPIO_InitStruct);

  /*Configure GPIO pins : RTC_CS_Pin TFT_DC_Pin */
  GPIO_InitStruct.Pin = RTC_CS_Pin|TFT_DC_Pin;
  GPIO_InitStruct.Mode = GPIO_MODE_OUTPUT_PP;
  GPIO_InitStruct.Pull = GPIO_NOPULL;
  GPIO_InitStruct.Speed = GPIO_SPEED_FREQ_HIGH;
  HAL_GPIO_Init(GPIOB, &GPIO_InitStruct);

  /*Configure GPIO pin : TP_IRQ_Pin */
  GPIO_InitStruct.Pin = TP_IRQ_Pin;
  GPIO_InitStruct.Mode = GPIO_MODE_IT_RISING_FALLING;
  GPIO_InitStruct.Pull = GPIO_PULLUP;
  HAL_GPIO_Init(TP_IRQ_GPIO_Port, &GPIO_InitStruct);

  /*Configure GPIO pin : SD_CS_Pin */
  GPIO_InitStruct.Pin = SD_CS_Pin;
  GPIO_InitStruct.Mode = GPIO_MODE_OUTPUT_PP;
  GPIO_InitStruct.Pull = GPIO_NOPULL;
  GPIO_InitStruct.Speed = GPIO_SPEED_FREQ_HIGH;
  HAL_GPIO_Init(SD_CS_GPIO_Port, &GPIO_InitStruct);

  /*Configure GPIO pins : GPIO_PD15_Pin CAN_TxD_Pin LCD_RS_Pin LCD_D4_Pin
                           LCD_D5_Pin LCD_D6_Pin LCD_D7_Pin */
  GPIO_InitStruct.Pin = GPIO_PD15_Pin|CAN_TxD_Pin|LCD_RS_Pin|LCD_D4_Pin
                          |LCD_D5_Pin|LCD_D6_Pin|LCD_D7_Pin;
  GPIO_InitStruct.Mode = GPIO_MODE_OUTPUT_PP;
  GPIO_InitStruct.Pull = GPIO_NOPULL;
  GPIO_InitStruct.Speed = GPIO_SPEED_FREQ_LOW;
  HAL_GPIO_Init(GPIOD, &GPIO_InitStruct);

  /*Configure GPIO pins : LCD_LED_Pin TFT_LED_Pin _485_TxD_Pin */
  GPIO_InitStruct.Pin = LCD_LED_Pin|TFT_LED_Pin|_485_TxD_Pin;
  GPIO_InitStruct.Mode = GPIO_MODE_OUTPUT_PP;
  GPIO_InitStruct.Pull = GPIO_NOPULL;
  GPIO_InitStruct.Speed = GPIO_SPEED_FREQ_LOW;
  HAL_GPIO_Init(GPIOC, &GPIO_InitStruct);

  /*Configure GPIO pins : CAN_RxD_Pin _485_RxD_Pin */
  GPIO_InitStruct.Pin = CAN_RxD_Pin|_485_RxD_Pin;
  GPIO_InitStruct.Mode = GPIO_MODE_INPUT;
  GPIO_InitStruct.Pull = GPIO_NOPULL;
  HAL_GPIO_Init(GPIOD, &GPIO_InitStruct);

  /* EXTI interrupt init*/
  HAL_NVIC_SetPriority(EXTI15_10_IRQn, 1, 0);
  HAL_NVIC_EnableIRQ(EXTI15_10_IRQn);

}

/* USER CODE BEGIN 4 */
void HAL_SPI_TxCpltCallback(SPI_HandleTypeDef *hspi)
{
  if(hspi == &hspi3)
  {
    dma_spi_cnt--;
    if(dma_spi_cnt==0)
    {
      HAL_SPI_DMAStop(&hspi3);
      dma_spi_cnt=1;
      dma_spi_fl=1;
    }
  }
}

void HAL_GPIO_EXTI_Callback (uint16_t GPIO_Pin)
{
	  switch(GPIO_Pin)
	  {
	  	  	case TP_IRQ_Pin:
				if(XPT2046_TouchPressed())
				{
					 uint16_t x = 0, y = 0;
					 if(XPT2046_TouchGetCoordinates(&x, &y))
					 {
						 GUI_touch(TFTstav,x,y);
						 IRQ_flag=true;
					 }
				}
	  	  		break;
	  	  	case IN_TL1_Pin:
	  	  		if(TFTstav==8)
	  	  		{
		  			HAL_TIM_Base_Start_IT(&htim4);
	  	  		}
	  	  		break;
	  	  	case IN_TL2_Pin:
	  	  		if(TFTstav==8)
	  	  		{
		  			HAL_TIM_Base_Start_IT(&htim5);
	  	  		}
	  	  		break;
	  }
}

void HAL_TIM_PeriodElapsedCallback(TIM_HandleTypeDef *htim)
{
  /* Prevent unused argument(s) compilation warning */
	UNUSED(htim);
	if(htim == &htim4)
	{
		if(HAL_GPIO_ReadPin(IN_TL1_GPIO_Port, IN_TL1_Pin)==RESET)
		{
	    	HAL_GPIO_TogglePin(OUT_LED2_GPIO_Port, OUT_LED2_Pin);
			HAL_TIM_Base_Stop_IT(&htim4);
		}
	}
	if(htim == &htim5)
	{
		if(HAL_GPIO_ReadPin(IN_TL2_GPIO_Port, IN_TL2_Pin)==RESET)
		{
			HAL_GPIO_TogglePin(OUT_LED3_GPIO_Port, OUT_LED3_Pin);
			HAL_TIM_Base_Stop_IT(&htim5);
		}
	}
	if(htim == &htim6)
	{
		switch(semafor)
		{
		case 0:
			HAL_GPIO_WritePin(OUT_LED2_GPIO_Port, OUT_LED2_Pin, SET);
			HAL_GPIO_WritePin(OUT_LED1_GPIO_Port, OUT_LED1_Pin, RESET);
			HAL_GPIO_WritePin(OUT_LED3_GPIO_Port, OUT_LED3_Pin, RESET);
			set_rgb (0,255,255);
			semafor=1;
			break;
		case 1:
			HAL_GPIO_WritePin(OUT_LED2_GPIO_Port, OUT_LED2_Pin, RESET);
			HAL_GPIO_WritePin(OUT_LED1_GPIO_Port, OUT_LED1_Pin, RESET);
			HAL_GPIO_WritePin(OUT_LED3_GPIO_Port, OUT_LED3_Pin, SET);
			set_rgb (0,0,255);
			semafor=2;
			break;
		case 2:
			HAL_GPIO_WritePin(OUT_LED2_GPIO_Port, OUT_LED2_Pin, RESET);
			HAL_GPIO_WritePin(OUT_LED1_GPIO_Port, OUT_LED1_Pin, SET);
			HAL_GPIO_WritePin(OUT_LED3_GPIO_Port, OUT_LED3_Pin, RESET);
			set_rgb (255,0,255);
			semafor=0;
			break;
		}
	}
}

/* USER CODE END 4 */

void Error_Handler(void)
{
}

/************************ (C) COPYRIGHT STMicroelectronics *****END OF FILE****/
